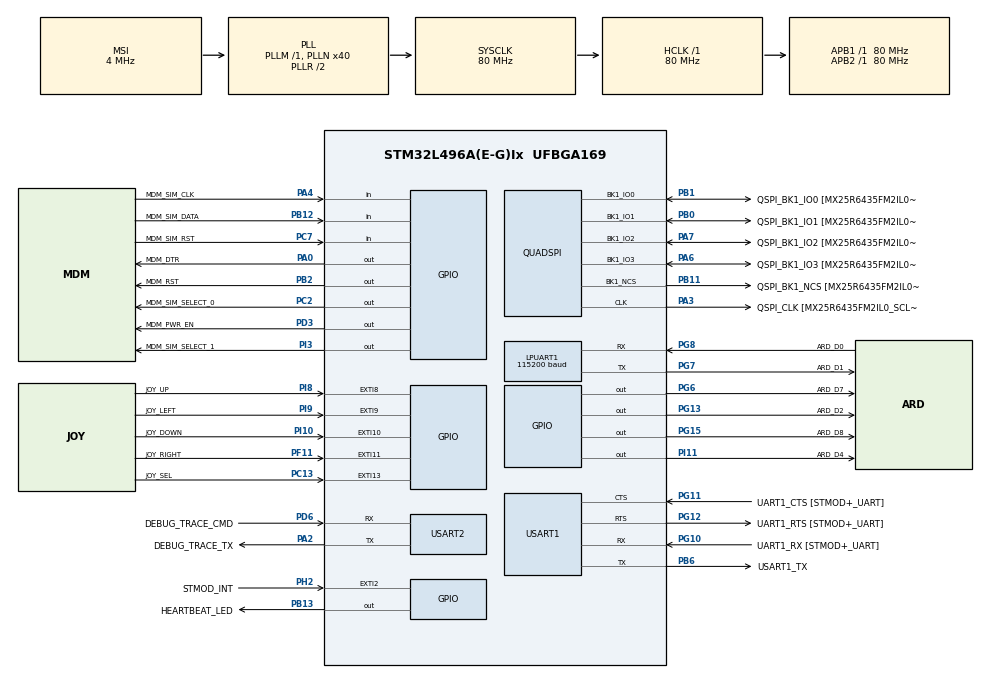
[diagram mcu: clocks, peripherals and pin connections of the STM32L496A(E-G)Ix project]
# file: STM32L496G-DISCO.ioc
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FREERTOS.INCLUDE_uxTaskGetStackHighWaterMark=1
FREERTOS.INCLUDE_vTaskDelayUntil=1
FREERTOS.Tasks01=defaultTask,0,128,StartDefaultTask,Default,NULL,Dynamic,NULL,NULL
FREERTOS.configTOTAL_HEAP_SIZE=18432
FREERTOS.configUSE_COUNTING_SEMAPHORES=1
FREERTOS.configUSE_TIMERS=1
LPUART1.BaudRate=115200
LPUART1.WordLength=UART_WORDLENGTH_8B
Mcu.Family=STM32L4
Mcu.Name=STM32L496A(E-G)Ix
Mcu.Package=UFBGA169
NVIC.EXTI15_10_IRQn=true\:5\:0\:false\:false\:true\:true\:true\:true
NVIC.EXTI9_5_IRQn=true\:5\:0\:false\:false\:true\:true\:true\:true
NVIC.LPUART1_IRQn=true\:5\:0\:false\:false\:true\:true\:true\:true
NVIC.PriorityGroup=NVIC_PRIORITYGROUP_4
NVIC.TIM3_IRQn=true\:0\:0\:false\:false\:true\:false\:false\:true
NVIC.TimeBase=TIM3_IRQn
NVIC.TimeBaseIP=TIM3
NVIC.USART1_IRQn=true\:5\:0\:false\:false\:true\:true\:true\:true
NVIC.USART2_IRQn=true\:5\:0\:false\:false\:true\:true\:true\:true
PA0.GPIO_Label=MDM_DTR
PA0.PinState=GPIO_PIN_RESET
PA0.Signal=GPIO_Output
PA1.GPIO_Label=ARD_A4
PA1.Signal=ADCx_IN6
PA10.GPIO_Label=USB_OTGFS_ID
PA10.Signal=USB_OTG_FS_ID
PA11.GPIO_Label=USB_OTGFS_DM
PA11.Signal=USB_OTG_FS_DM
PA12.GPIO_Label=USB_OTGFS_DP
PA12.Signal=USB_OTG_FS_DP
PA13\ (JTMS/SWDIO).GPIO_Label=SWDIO
PA13\ (JTMS/SWDIO).Signal=SYS_JTMS-SWDIO
PA14\ (JTCK/SWCLK).GPIO_Label=SWCLK
PA14\ (JTCK/SWCLK).Signal=SYS_JTCK-SWCLK
PA15\ (JTDI).GPIO_Label=ARD_D10
PA15\ (JTDI).Signal=SPI1_NSS
PA2.GPIO_Label=DEBUG_TRACE_TX
PA2.Mode=Asynchronous
PA2.Signal=USART2_TX
PA3.GPIO_Label=QSPI_CLK [MX25R6435FM2IL0_SCLK]
PA3.Mode=Single Bank 1
PA3.Signal=QUADSPI_CLK
PA4.GPIO_Label=MDM_SIM_CLK
PA4.Signal=GPIO_Input
PA5.GPIO_Label=ARD_D13
PA5.Signal=SPI1_SCK
PA6.GPIO_Label=QSPI_BK1_IO3 [MX25R6435FM2IL0_SIO3]
PA6.Mode=Single Bank 1
PA6.Signal=QUADSPI_BK1_IO3
PA7.GPIO_Label=QSPI_BK1_IO2 [MX25R6435FM2IL0_SIO2]
PA7.Mode=Single Bank 1
PA7.Signal=QUADSPI_BK1_IO2
PA8.GPIO_Label=DCMI_CLK
PA8.Signal=LPTIM2_OUT
PA9.GPIO_Label=USB_OTGFS_VBUS
PA9.Signal=USB_OTG_FS_VBUS
PB0.GPIO_Label=QSPI_BK1_IO1 [MX25R6435FM2IL0_SIO1]
PB0.Mode=Single Bank 1
PB0.Signal=QUADSPI_BK1_IO1
PB1.GPIO_Label=QSPI_BK1_IO0 [MX25R6435FM2IL0_SIO0]
PB1.Mode=Single Bank 1
PB1.Signal=QUADSPI_BK1_IO0
PB10.GPIO_Label=SAI1_CKA [SLCK_CS42L51]
PB10.Signal=SAI1_SCK_A
PB11.GPIO_Label=QSPI_BK1_NCS [MX25R6435FM2IL0_CS]
PB11.Mode=Single Bank 1
PB11.Signal=QUADSPI_BK1_NCS
PB12.GPIO_Label=MDM_SIM_DATA
PB12.Signal=GPIO_Input
PB13.GPIO_Label=HEARTBEAT_LED
PB13.GPIO_ModeDefaultOutputPP=GPIO_MODE_OUTPUT_OD
PB13.GPIO_PuPd=GPIO_NOPULL
PB13.Signal=GPIO_Output
PB14.GPIO_Label=I2C2_SDA [CS42L51_SDA]
PB14.Signal=I2C2_SDA
PB15.GPIO_Label=SPI2_MOSI
PB15.Signal=SPI2_MOSI
PB2.GPIO_Label=MDM_RST
PB2.PinState=GPIO_PIN_SET
PB2.Signal=GPIO_Output
PB3\ (JTDO/TRACESWO).GPIO_Label=SWO
PB3\ (JTDO/TRACESWO).Signal=SYS_JTDO-SWO
PB4\ (NJTRST).GPIO_Label=ARD_D12
PB4\ (NJTRST).Signal=SPI1_MISO
PB5.GPIO_Label=ARD_D11
PB5.Signal=SPI1_MOSI
PB6.GPIO_Label=USART1_TX
PB6.Mode=Asynchronous
PB6.Signal=USART1_TX
PB7.GPIO_Label=I2C1_SDA
PB7.Signal=I2C1_SDA
PB9.GPIO_Label=ARD_D5
PB9.Signal=S_TIM4_CH4
PC0.GPIO_Label=ARD_A5
PC0.Signal=ADCx_IN1
PC1.Signal=ADCx_IN2
PC10.GPIO_Label=uSD_D2
PC10.Signal=SDMMC1_D2
PC11.GPIO_Label=uSD_D3
PC11.Signal=SDMMC1_D3
PC12.GPIO_Label=uSD_CLK
PC12.Signal=SDMMC1_CK
PC13.GPIO_Label=JOY_SEL
PC13.GPIO_PuPd=GPIO_PULLDOWN
PC13.Signal=GPXTI13
PC14-OSC32_IN\ (PC14).Signal=RCC_OSC32_IN
PC15-OSC32_OUT\ (PC15).Signal=RCC_OSC32_OUT
PC2.GPIO_Label=MDM_SIM_SELECT_0
PC2.GPIO_PuPd=GPIO_PULLDOWN
PC2.Signal=GPIO_Output
PC3.GPIO_Label=ARD_A2
PC3.Signal=ADCx_IN4
PC4.GPIO_Label=ARD_A0
PC4.Signal=ADCx_IN13
PC7.GPIO_Label=MDM_SIM_RST
PC7.Signal=GPIO_Input
PC8.GPIO_Label=uSD_D0
PC8.Signal=SDMMC1_D0
PC9.GPIO_Label=uSD_D1
PC9.Signal=SDMMC1_D1
PD0.GPIO_Label=D2 [D2_ IS66WV51216EBLL]
PD0.Signal=FMC_D2_DA2
PD1.GPIO_Label=D3 [D3_IS66WV51216EBLL]
PD1.Signal=FMC_D3_DA3
PD10.GPIO_Label=D15 [D15_IS66WV51216EBLL]
PD10.Signal=FMC_D15_DA15
PD11.GPIO_Label=PSRAM_A16 [A16_IS66WV51216EBLL]
PD11.Signal=FMC_A16_CLE
PD12.GPIO_Label=PSRAM_A17 [A17_IS66WV51216EBLL]
PD12.Signal=FMC_A17_ALE
PD13.GPIO_Label=PSRAM_A18_LCD_RS [A18_IS66WV51216EBLL]
PD13.Signal=FMC_A18
PD14.GPIO_Label=D0 [D0_IS66WV51216EBLL]
PD14.Signal=FMC_D0_DA0
PD15.GPIO_Label=D1 [D1_IS66WV51216EBLL]
PD15.Signal=FMC_D1_DA1
PD2.GPIO_Label=uSD_CMD
PD2.Signal=SDMMC1_CMD
PD3.GPIO_Label=MDM_PWR_EN
PD3.PinState=GPIO_PIN_SET
PD3.Signal=GPIO_Output
PD4.GPIO_Label=OE [OE_IS66WV51216EBLL]
PD4.Signal=FMC_NOE
PD5.GPIO_Label=WE [WE_IS66WV51216EBLL]
PD5.Signal=FMC_NWE
PD6.GPIO_Label=DEBUG_TRACE_CMD
PD6.Mode=Asynchronous
PD6.Signal=USART2_RX
PD7.GPIO_Label=LCD_NE
PD7.Signal=FMC_NE1
PD8.GPIO_Label=D13 [D13_IS66WV51216EBLL]
PD8.Signal=FMC_D13_DA13
PD9.GPIO_Label=D14 [D14_IS66WV51216EBLL]
PD9.Signal=FMC_D14_DA14
PE0.GPIO_Label=PSRAM_NBL0 [LB_IS66WV51216EBLL]
PE0.Signal=FMC_NBL0
PE1.GPIO_Label=PSRAM_NBL1 [UB_IS66WV51216EBLL]
PE1.Signal=FMC_NBL1
PE10.GPIO_Label=D7 [D7_IS66WV51216EBLL]
PE10.Signal=FMC_D7_DA7
PE11.GPIO_Label=D8  [D8_IS66WV51216EBLL]
PE11.Signal=FMC_D8_DA8
PE12.GPIO_Label=D9 [D9_IS66WV51216EBLL]
PE12.Signal=FMC_D9_DA9
PE13.GPIO_Label=D10 [D10_IS66WV51216EBLL]
PE13.Signal=FMC_D10_DA10
PE14.GPIO_Label=D11 [D11_IS66WV51216EBLL]
PE14.Signal=FMC_D11_DA11
PE15.GPIO_Label=D12 [D12_IS66WV51216EBLL]
PE15.Signal=FMC_D12_DA12
PE2.GPIO_Label=SAI1_MCKA [MCLK_CS42L51]
PE2.Signal=SAI1_MCLK_A
PE3.GPIO_Label=SAI1_SDB [SDOUT_CS42L51]
PE3.Signal=SAI1_SD_B
PE4.GPIO_Label=SAI1_FSA [LRCK_CS42L51]]
PE4.Signal=SAI1_FS_A
PE5.GPIO_Label=DCMI_D6
PE5.Signal=DCMI_D6
PE6.GPIO_Label=SAI1_SDA [SDIN_CS42L51]
PE6.Signal=SAI1_SD_A
PE7.GPIO_Label=D4 [D4_IS66WV51216EBLL]
PE7.Signal=FMC_D4_DA4
PE8.GPIO_Label=D5 [D5_IS66WV51216EBLL]
PE8.Signal=FMC_D5_DA5
PE9.GPIO_Label=D6 [D6_IS66WV51216EBLL]
PE9.Signal=FMC_D6_DA6
PF0.GPIO_Label=PSRAM_A0 [A0_IS66WV51216EBLL]
PF0.Signal=FMC_A0
PF1.GPIO_Label=PSRAM_A1 [A1_IS66WV51216EBLL]
PF1.Signal=FMC_A1
PF10.GPIO_Label=ARD_A3
PF10.Signal=ADC3_IN13
PF11.GPIO_Label=JOY_RIGHT
PF11.GPIO_ModeDefaultEXTI=GPIO_MODE_IT_RISING
PF11.GPIO_PuPd=GPIO_PULLDOWN
PF11.Signal=GPXTI11
PF12.GPIO_Label=PSRAM_A6 [A6_IS66WV51216EBLL]
PF12.Signal=FMC_A6
PF13.GPIO_Label=PSRAM_A7 [A7_IS66WV51216EBLL]
PF13.Signal=FMC_A7
PF14.GPIO_Label=PSRAM_A8 [A8_IS66WV51216EBLL]
PF14.Signal=FMC_A8
PF15.GPIO_Label=PSRAM_A9 [A9_IS66WV51216EBLL]
PF15.Signal=FMC_A9
PF2.GPIO_Label=PSRAM_A2 [A2_IS66WV51216EBLL]
PF2.Signal=FMC_A2
PF3.GPIO_Label=PSRAM_A3 [A3_IS66WV51216EBLL]
PF3.Signal=FMC_A3
PF4.GPIO_Label=PSRAM_A4 [A4_IS66WV51216EBLL]
PF4.Signal=FMC_A4
PF5.GPIO_Label=PSRAM_A5 [A5_IS66WV51216EBLL]
PF5.Signal=FMC_A5
PG0.GPIO_Label=PSRAM_A10 [A10_IS66WV51216EBLL]
PG0.Signal=FMC_A10
PG1.GPIO_Label=PSRAM_A11 [A11_IS66WV51216EBLL]
PG1.Signal=FMC_A11
PG10.GPIO_Label=UART1_RX [STMOD+_UART]
PG10.Mode=Asynchronous
PG10.Signal=USART1_RX
PG11.GPIO_Label=UART1_CTS [STMOD+_UART]
PG11.Mode=CTS_RTS
PG11.Signal=USART1_CTS
PG12.GPIO_Label=UART1_RTS [STMOD+_UART]
PG12.Mode=CTS_RTS
PG12.Signal=USART1_RTS
PG13.GPIO_Label=ARD_D2
PG13.Signal=GPIO_Output
PG15.GPIO_Label=ARD_D8
PG15.Signal=GPIO_Output
PG2.GPIO_Label=PSRAM_A12 [A12_IS66WV51216EBLL]
PG2.Signal=FMC_A12
PG3.GPIO_Label=PSRAM_A13 [A13_IS66WV51216EBLL]
PG3.Signal=FMC_A13
PG4.GPIO_Label=PSRAM_A14 [A14_IS66WV51216EBLL]
PG4.Signal=FMC_A14
PG5.GPIO_Label=PSRAM_A15 [A15_IS66WV51216EBLL]
PG5.Signal=FMC_A15
PG6.GPIO_Label=ARD_D7
PG6.Signal=GPIO_Output
PG7.GPIO_Label=ARD_D1
PG7.Mode=Asynchronous
PG7.Signal=LPUART1_TX
PG8.GPIO_Label=ARD_D0
PG8.Mode=Asynchronous
PG8.Signal=LPUART1_RX
PG9.GPIO_Label=PSRAM_NE [CS1_IS66WV51216EBLL]
PG9.Signal=FMC_NE2
PH10.GPIO_Label=DCMI_D1
PH10.Signal=DCMI_D1
PH11.GPIO_Label=DCMI_D2
PH11.Signal=DCMI_D2
PH12.GPIO_Label=DCMI_D3
PH12.Signal=DCMI_D3
PH13.GPIO_Label=ARD_D9
PH13.Signal=TIM8_CH1N
PH14.GPIO_Label=DCMI_D4
PH14.Signal=DCMI_D4
PH15.GPIO_Label=ARD_D3
PH15.Signal=TIM8_CH3N
PH2.GPIO_Label=STMOD_INT
PH2.Signal=GPXTI2
PH4.GPIO_Label=I2C2_SCL [SCL_CS42L51]
PH4.Signal=I2C2_SCL
PH5.GPIO_Label=DCMI_PIXCK
PH5.Signal=DCMI_PIXCLK
PH8.GPIO_Label=DCMI_HSYNC
PH8.Signal=DCMI_HSYNC
PH9.GPIO_Label=DCMI_D0
PH9.Signal=DCMI_D0
PI1.GPIO_Label=SPI2_CLK [STMOD+_SPI]
PI1.Signal=SPI2_SCK
PI10.GPIO_Label=JOY_DOWN
PI10.GPIO_PuPd=GPIO_PULLDOWN
PI10.Signal=GPXTI10
PI11.GPIO_Label=ARD_D4
PI11.Signal=GPIO_Output
PI2.GPIO_Label=SPI2_MISO [STMOD+_SPI]
PI2.Signal=SPI2_MISO
PI3.GPIO_Label=MDM_SIM_SELECT_1
PI3.GPIO_PuPd=GPIO_PULLDOWN
PI3.Signal=GPIO_Output
PI4.GPIO_Label=DCMI_D5
PI4.Signal=DCMI_D5
PI5.GPIO_Label=DCMI_VSYNC
PI5.Signal=DCMI_VSYNC
PI6.GPIO_Label=ARD_D6
PI6.Signal=S_TIM8_CH2
PI7.GPIO_Label=DCMI_D7
PI7.Signal=DCMI_D7
PI8.GPIO_Label=JOY_UP
PI8.GPIO_ModeDefaultEXTI=GPIO_MODE_IT_RISING
PI8.GPIO_PuPd=GPIO_PULLDOWN
PI8.Signal=GPXTI8
PI9.GPIO_Label=JOY_LEFT
PI9.GPIO_ModeDefaultEXTI=GPIO_MODE_IT_RISING
PI9.GPIO_PuPd=GPIO_PULLDOWN
PI9.Signal=GPXTI9
ProjectManager.HeapSize=0x200
ProjectManager.StackSize=0x400
ProjectManager.TargetToolchain=STM32CubeIDE
QUADSPI.ClockPrescaler=2
QUADSPI.FifoThreshold=4
QUADSPI.FlashSize=23
QUADSPI.SampleShifting=QSPI_SAMPLE_SHIFTING_HALFCYCLE
RCC.ADCFreq_Value=40000000
RCC.AHBFreq_Value=80000000
RCC.APB1Freq_Value=80000000
RCC.APB1TimFreq_Value=80000000
RCC.APB2Freq_Value=80000000
RCC.APB2TimFreq_Value=80000000
RCC.CortexFreq_Value=80000000
RCC.HCLKFreq_Value=80000000
RCC.HSE_VALUE=8000000
RCC.HSI48_VALUE=48000000
RCC.HSI_VALUE=16000000
RCC.LSE_VALUE=32768
RCC.MSI_VALUE=4000000
RCC.PLLN=40
RCC.PLLSAI1N=20
RCC.SYSCLKFreq_VALUE=80000000
RCC.SYSCLKSource=RCC_SYSCLKSOURCE_PLLCLK
RCC.USBFreq_Value=40000000
RCC.VCOOutputFreq_Value=160000000
SH.ADCx_IN1.0=ADC2_IN1
SH.ADCx_IN13.0=ADC1_IN13
SH.ADCx_IN2.0=ADC2_IN2
SH.ADCx_IN4.0=ADC1_IN4
SH.ADCx_IN6.0=ADC2_IN6
SH.FMC_A0.0=FMC_A0
SH.FMC_A1.0=FMC_A1
SH.FMC_A10.0=FMC_A10
SH.FMC_A11.0=FMC_A11
SH.FMC_A12.0=FMC_A12
SH.FMC_A13.0=FMC_A13
SH.FMC_A14.0=FMC_A14
SH.FMC_A15.0=FMC_A15
SH.FMC_A16_CLE.0=FMC_A16
SH.FMC_A17_ALE.0=FMC_A17
SH.FMC_A18.0=FMC_A18
SH.FMC_A2.0=FMC_A2
SH.FMC_A3.0=FMC_A3
SH.FMC_A4.0=FMC_A4
SH.FMC_A5.0=FMC_A5
SH.FMC_A6.0=FMC_A6
SH.FMC_A7.0=FMC_A7
SH.FMC_A8.0=FMC_A8
SH.FMC_A9.0=FMC_A9
SH.FMC_D0_DA0.0=FMC_D0
SH.FMC_D10_DA10.0=FMC_D10
SH.FMC_D11_DA11.0=FMC_D11
SH.FMC_D12_DA12.0=FMC_D12
SH.FMC_D13_DA13.0=FMC_D13
SH.FMC_D14_DA14.0=FMC_D14
SH.FMC_D15_DA15.0=FMC_D15
SH.FMC_D1_DA1.0=FMC_D1
SH.FMC_D2_DA2.0=FMC_D2
SH.FMC_D3_DA3.0=FMC_D3
SH.FMC_D4_DA4.0=FMC_D4
SH.FMC_D5_DA5.0=FMC_D5
SH.FMC_D6_DA6.0=FMC_D6
SH.FMC_D7_DA7.0=FMC_D7
SH.FMC_D8_DA8.0=FMC_D8
SH.FMC_D9_DA9.0=FMC_D9
SH.FMC_NBL0.0=FMC_NBL0
SH.FMC_NBL1.0=FMC_NBL1
SH.FMC_NOE.0=FMC_NOE
SH.FMC_NWE.0=FMC_NWE
SH.S_TIM4_CH4.0=TIM4_CH4
SH.S_TIM8_CH2.0=TIM8_CH2
USART1.VirtualMode-Asynchronous=VM_ASYNC
USART1.WordLength=WORDLENGTH_8B
USART2.VirtualMode-Asynchronous=VM_ASYNC
USART2.WordLength=WORDLENGTH_8B
VP_FREERTOS_VS_CMSIS_V1.Mode=CMSIS_V1
VP_RNG_VS_RNG.Mode=RNG_Activate
VP_RTC_VS_RTC_Activate.Mode=RTC_Enabled
VP_SYS_VS_tim3.Mode=TIM3
board=STM32L496G-DISCO

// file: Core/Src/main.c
/* USER CODE BEGIN Header */
/**
  ******************************************************************************
  * @file           : main.c
  * @brief          : Main program body
  ******************************************************************************
  * @attention
  *
  * <h2><center>&copy; Copyright (c) 2021 STMicroelectronics.
  * All rights reserved.</center></h2>
  *
  * This software component is licensed by ST under Ultimate Liberty license
  * SLA0044, the "License"; You may not use this file except in compliance with
  * the License. You may obtain a copy of the License at:
  *                             www.st.com/SLA0044
  *
  ******************************************************************************
  */
/* USER CODE END Header */
#include "main.h"
#include "cmsis_os.h"
#include "usart.h"
#include "quadspi.h"
#include "rng.h"
#include "rtc.h"
#include "gpio.h"

/* USER CODE BEGIN PV */
UART_HandleTypeDef *const g_console_huart = &huart2;
/* USER CODE END PV */

void SystemClock_Config(void);
void MX_FREERTOS_Init(void);

int main(void)
{

  /* MCU Configuration--------------------------------------------------------*/

  /* Reset of all peripherals, Initializes the Flash interface and the Systick. */
  HAL_Init();

  /* Configure the system clock */
  SystemClock_Config();

  /* Initialize all configured peripherals */
  MX_GPIO_Init();
  MX_USART2_UART_Init();
  MX_USART1_UART_Init();
  MX_RTC_Init();
  MX_LPUART1_UART_Init();
  MX_RNG_Init();
  MX_QUADSPI_Init();

  /* Call init function for freertos objects (in freertos.c) */
  MX_FREERTOS_Init();
  /* Start scheduler */
  osKernelStart();

  /* We should never get here as control is now taken by the scheduler */
  /* Infinite loop */
  while (1)
  {

  }
}

void SystemClock_Config(void)
{
  RCC_OscInitTypeDef RCC_OscInitStruct = {0};
  RCC_ClkInitTypeDef RCC_ClkInitStruct = {0};
  RCC_PeriphCLKInitTypeDef PeriphClkInit = {0};

  /** Initializes the RCC Oscillators according to the specified parameters
  * in the RCC_OscInitTypeDef structure.
  */
  RCC_OscInitStruct.OscillatorType = RCC_OSCILLATORTYPE_LSI|RCC_OSCILLATORTYPE_MSI;
  RCC_OscInitStruct.LSIState = RCC_LSI_ON;
  RCC_OscInitStruct.MSIState = RCC_MSI_ON;
  RCC_OscInitStruct.MSICalibrationValue = 0;
  RCC_OscInitStruct.MSIClockRange = RCC_MSIRANGE_6;
  RCC_OscInitStruct.PLL.PLLState = RCC_PLL_ON;
  RCC_OscInitStruct.PLL.PLLSource = RCC_PLLSOURCE_MSI;
  RCC_OscInitStruct.PLL.PLLM = 1;
  RCC_OscInitStruct.PLL.PLLN = 40;
  RCC_OscInitStruct.PLL.PLLP = RCC_PLLP_DIV2;
  RCC_OscInitStruct.PLL.PLLQ = RCC_PLLQ_DIV2;
  RCC_OscInitStruct.PLL.PLLR = RCC_PLLR_DIV2;
  if (HAL_RCC_OscConfig(&RCC_OscInitStruct) != HAL_OK)
  {
    Error_Handler();
  }
  /** Initializes the CPU, AHB and APB buses clocks
  */
  RCC_ClkInitStruct.ClockType = RCC_CLOCKTYPE_HCLK|RCC_CLOCKTYPE_SYSCLK
                              |RCC_CLOCKTYPE_PCLK1|RCC_CLOCKTYPE_PCLK2;
  RCC_ClkInitStruct.SYSCLKSource = RCC_SYSCLKSOURCE_PLLCLK;
  RCC_ClkInitStruct.AHBCLKDivider = RCC_SYSCLK_DIV1;
  RCC_ClkInitStruct.APB1CLKDivider = RCC_HCLK_DIV1;
  RCC_ClkInitStruct.APB2CLKDivider = RCC_HCLK_DIV1;

  if (HAL_RCC_ClockConfig(&RCC_ClkInitStruct, FLASH_LATENCY_4) != HAL_OK)
  {
    Error_Handler();
  }
  PeriphClkInit.PeriphClockSelection = RCC_PERIPHCLK_RTC|RCC_PERIPHCLK_USART1
                              |RCC_PERIPHCLK_USART2|RCC_PERIPHCLK_LPUART1
                              |RCC_PERIPHCLK_RNG;
  PeriphClkInit.Usart1ClockSelection = RCC_USART1CLKSOURCE_PCLK2;
  PeriphClkInit.Usart2ClockSelection = RCC_USART2CLKSOURCE_PCLK1;
  PeriphClkInit.Lpuart1ClockSelection = RCC_LPUART1CLKSOURCE_PCLK1;
  PeriphClkInit.RTCClockSelection = RCC_RTCCLKSOURCE_LSI;
  PeriphClkInit.RngClockSelection = RCC_RNGCLKSOURCE_PLLSAI1;
  PeriphClkInit.PLLSAI1.PLLSAI1Source = RCC_PLLSOURCE_MSI;
  PeriphClkInit.PLLSAI1.PLLSAI1M = 1;
  PeriphClkInit.PLLSAI1.PLLSAI1N = 20;
  PeriphClkInit.PLLSAI1.PLLSAI1P = RCC_PLLP_DIV2;
  PeriphClkInit.PLLSAI1.PLLSAI1Q = RCC_PLLQ_DIV2;
  PeriphClkInit.PLLSAI1.PLLSAI1R = RCC_PLLR_DIV2;
  PeriphClkInit.PLLSAI1.PLLSAI1ClockOut = RCC_PLLSAI1_48M2CLK;
  if (HAL_RCCEx_PeriphCLKConfig(&PeriphClkInit) != HAL_OK)
  {
    Error_Handler();
  }
  /** Configure the main internal regulator output voltage
  */
  if (HAL_PWREx_ControlVoltageScaling(PWR_REGULATOR_VOLTAGE_SCALE1) != HAL_OK)
  {
    Error_Handler();
  }
}

 /**
  * @brief  Period elapsed callback in non blocking mode
  * @note   This function is called  when TIM3 interrupt took place, inside
  * HAL_TIM_IRQHandler(). It makes a direct call to HAL_IncTick() to increment
  * a global variable "uwTick" used as application time base.
  * @param  htim : TIM handle
  * @retval None
  */
void HAL_TIM_PeriodElapsedCallback(TIM_HandleTypeDef *htim)
{
  if (htim->Instance == TIM3) {
    HAL_IncTick();
  }
}

void Error_Handler(void)
{
  __disable_irq();
  while (1)
  {
  }
}

/************************ (C) COPYRIGHT STMicroelectronics *****END OF FILE****/

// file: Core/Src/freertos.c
/* USER CODE BEGIN Header */
/**
  ******************************************************************************
  * File Name          : freertos.c
  * Description        : Code for freertos applications
  ******************************************************************************
  * @attention
  *
  * <h2><center>&copy; Copyright (c) 2021 STMicroelectronics.
  * All rights reserved.</center></h2>
  *
  * This software component is licensed by ST under Ultimate Liberty license
  * SLA0044, the "License"; You may not use this file except in compliance with
  * the License. You may obtain a copy of the License at:
  *                             www.st.com/SLA0044
  *
  ******************************************************************************
  */
/* USER CODE END Header */

#include "FreeRTOS.h"
#include "task.h"
#include "main.h"
#include "cmsis_os.h"

/* USER CODE BEGIN Includes */
#include "application.h"
/* USER CODE END Includes */

osThreadId defaultTaskHandle;

void StartDefaultTask(void const * argument);

void MX_FREERTOS_Init(void); /* (MISRA C 2004 rule 8.1) */

/* GetIdleTaskMemory prototype (linked to static allocation support) */
void vApplicationGetIdleTaskMemory( StaticTask_t **ppxIdleTaskTCBBuffer, StackType_t **ppxIdleTaskStackBuffer, uint32_t *pulIdleTaskStackSize );

/* GetTimerTaskMemory prototype (linked to static allocation support) */
void vApplicationGetTimerTaskMemory( StaticTask_t **ppxTimerTaskTCBBuffer, StackType_t **ppxTimerTaskStackBuffer, uint32_t *pulTimerTaskStackSize );

/* USER CODE BEGIN GET_IDLE_TASK_MEMORY */
static StaticTask_t xIdleTaskTCBBuffer;
static StackType_t xIdleStack[configMINIMAL_STACK_SIZE];

void vApplicationGetIdleTaskMemory( StaticTask_t **ppxIdleTaskTCBBuffer, StackType_t **ppxIdleTaskStackBuffer, uint32_t *pulIdleTaskStackSize )
{
  *ppxIdleTaskTCBBuffer = &xIdleTaskTCBBuffer;
  *ppxIdleTaskStackBuffer = &xIdleStack[0];
  *pulIdleTaskStackSize = configMINIMAL_STACK_SIZE;
  /* place for user code */
}
/* USER CODE END GET_IDLE_TASK_MEMORY */

/* USER CODE BEGIN GET_TIMER_TASK_MEMORY */
static StaticTask_t xTimerTaskTCBBuffer;
static StackType_t xTimerStack[configTIMER_TASK_STACK_DEPTH];

void vApplicationGetTimerTaskMemory( StaticTask_t **ppxTimerTaskTCBBuffer, StackType_t **ppxTimerTaskStackBuffer, uint32_t *pulTimerTaskStackSize )
{
  *ppxTimerTaskTCBBuffer = &xTimerTaskTCBBuffer;
  *ppxTimerTaskStackBuffer = &xTimerStack[0];
  *pulTimerTaskStackSize = configTIMER_TASK_STACK_DEPTH;
  /* place for user code */
}
/* USER CODE END GET_TIMER_TASK_MEMORY */

void MX_FREERTOS_Init(void) {
  /* USER CODE BEGIN Init */
  application_init();
  /* USER CODE END Init */

  /* Create the thread(s) */
  /* definition and creation of defaultTask */
  osThreadDef(defaultTask, StartDefaultTask, osPriorityNormal, 0, 128);
  defaultTaskHandle = osThreadCreate(osThread(defaultTask), NULL);

}

void StartDefaultTask(void const * argument)
{
  for(;;)
  {
    osDelay(1);
  }
}

/************************ (C) COPYRIGHT STMicroelectronics *****END OF FILE****/
